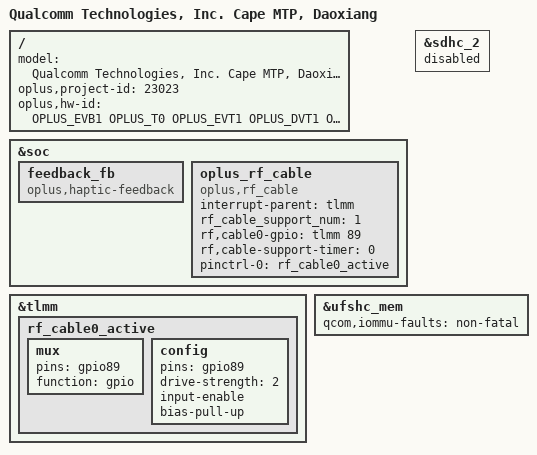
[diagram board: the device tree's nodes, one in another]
/dts-v1/;
/plugin/;
#include <dt-bindings/oplus/hw-id.h>
#include "../qcom/cape-mtp-pm8010-overlay.dts"
#include "cape_overlay_common.dtsi"
#include "oplus_chg/oplus-chg-23023.dtsi"
#include "daoxiang_23023_overlay_common.dtsi"
#include <dt-bindings/clock/qcom,rpmh.h>
#include "nfc/daoxiang-23023-nfc-sn110.dtsi"
#include "oplus_sensor/daoxiang-23023-cape-oplus-sensor.dtsi"
#include "oplus_uff/oplus_uff_23023.dtsi"

/ {
        model = "Qualcomm Technologies, Inc. Cape MTP, Daoxiang";
        oplus,project-id = <23023>;
        oplus,hw-id = <OPLUS_EVB1 OPLUS_T0 OPLUS_EVT1 OPLUS_DVT1 OPLUS_PVT1>;
};

&soc {
	feedback_fb: feedback_fb {
		compatible = "oplus,haptic-feedback";
	};
};

&tlmm {
  rf_cable0_active: rf_cable0_active {
    mux {
      pins = "gpio89";
      function = "gpio";
    };
    config {
      pins = "gpio89";
      drive-strength = <2>;
      input-enable;
      bias-pull-up;
    };
  };
};

&sdhc_2 {
    status = "disabled";

};

&soc {
  oplus_rf_cable {
    compatible = "oplus,rf_cable";
    interrupt-parent = <&tlmm>;
    rf_cable_support_num = <1>;
    rf,cable0-gpio = <&tlmm 89 0>;
    rf,cable-support-timer = <0>;
    pinctrl-names = "rf_cable_active";
    pinctrl-0 = <&rf_cable0_active>;
  };
};

&ufshc_mem{
  qcom,iommu-faults = "non-fatal";
};
